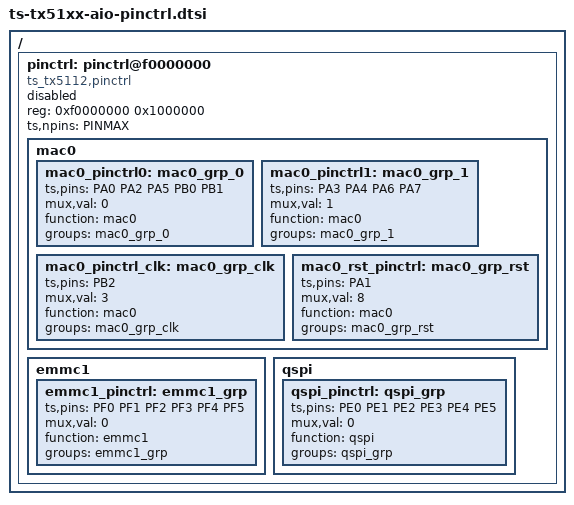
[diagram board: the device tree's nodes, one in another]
/*
 * dts file for tsingmicro tx5112
 *
 * Copyright 2022 Tsingmicro, Inc.
 *
 * This program is free software; you can redistribute it and/or
 * modify it under the terms of the GNU General Public License as
 * published by the Free Software Foundation; either version 2 of
 * the License, or (at your option) any later version.
 */

#include <dt-bindings/pinctrl/pinctrl-ts-tx5112.h>
/ {
		pinctrl: pinctrl@f0000000 {
			compatible = "ts_tx5112,pinctrl";
			status = "disabled";
			reg = <0xf0000000 0x1000000>;
			ts,npins = <PINMAX>;
			mac0 {
				//MAC_EPHY_CLK  MAC_TXEN MAC_RXDV MAC_MDC MAC_MDIO
				mac0_pinctrl0: mac0_grp_0 {
					ts,pins = <PA0 PA2 PA5 PB0 PB1>;
					mux,val = <0>;
					function = "mac0";
					groups = "mac0_grp_0";
				};
				//MAC_TXD0 MAC_TXD1 MAC_RXD0 MAC_RXD1
				mac0_pinctrl1: mac0_grp_1 {
					ts,pins = <PA3 PA4 PA6 PA7>;
					mux,val = <1>;
					function = "mac0";
					groups = "mac0_grp_1";
				};
				mac0_pinctrl_clk: mac0_grp_clk {
					ts,pins = <PB2>;
					mux,val = <3>;
					function = "mac0";
					groups = "mac0_grp_clk";
				};
				mac0_rst_pinctrl: mac0_grp_rst {
					ts,pins = <PA1>;
					mux,val = <8>;
					function = "mac0";
					groups = "mac0_grp_rst";
				};
			};
			emmc1 {
				emmc1_pinctrl: emmc1_grp {
					ts,pins = <PF0 PF1 PF2 PF3 PF4 PF5>;
					mux,val = <0>;
					function = "emmc1";
					groups = "emmc1_grp";
				};
			};
			qspi {
				qspi_pinctrl: qspi_grp {
					ts,pins = <PE0 PE1 PE2 PE3 PE4 PE5>;
					mux,val = <0>;
					function = "qspi";
					groups = "qspi_grp";
				};
			};

		};
};
